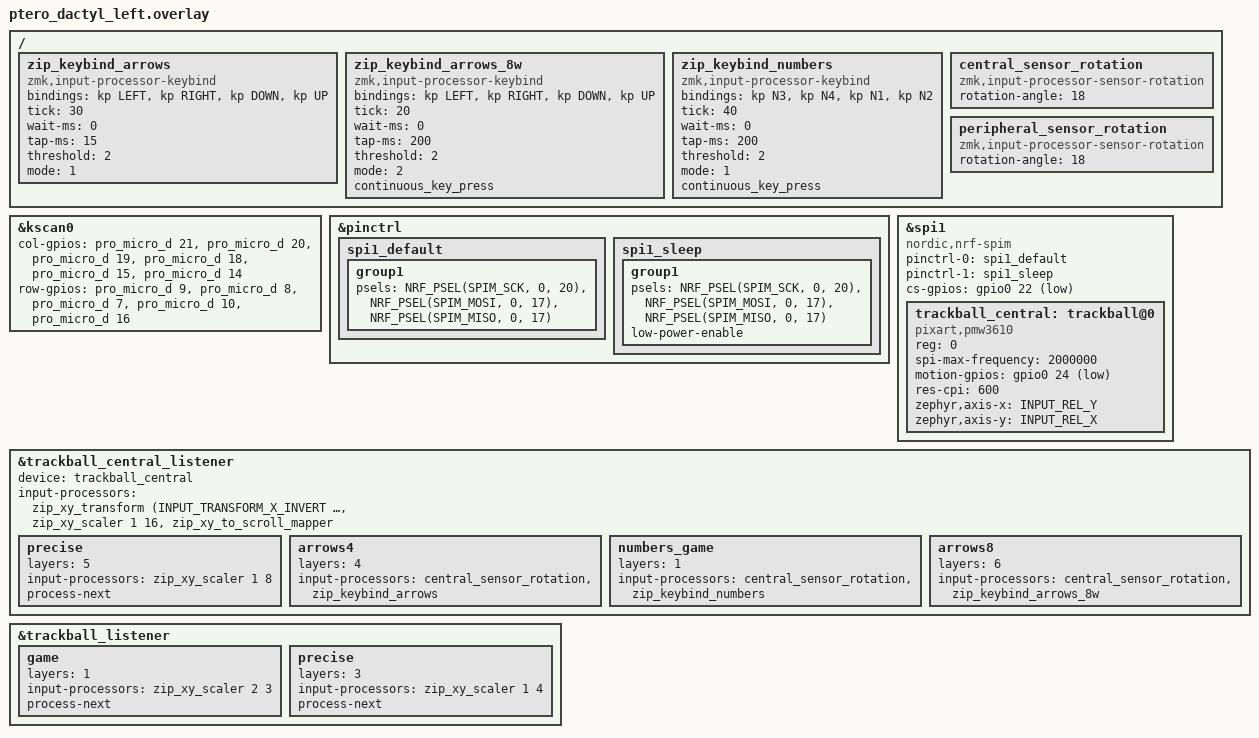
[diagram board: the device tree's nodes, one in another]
// This file was generated from a template. Edit it to match your keyboard.
// See https://zmk.dev/docs/development/hardware-integration/new-shield for more
// instructions.

#include "ptero_dactyl.dtsi"
#include <dt-bindings/zmk/input_transform.h>
#include <zephyr/dt-bindings/input/input-event-codes.h>
#include <input/processors.dtsi>

&kscan0 {
    // Replace these comments with the GPIO pins in the matrix for the left side.
    // See https://zmk.dev/docs/development/hardware-integration/new-shield#shield-overlays
    col-gpios
        = <&pro_micro_d 21 GPIO_ACTIVE_HIGH>
        , <&pro_micro_d 20 GPIO_ACTIVE_HIGH>
        , <&pro_micro_d 19 GPIO_ACTIVE_HIGH>
        , <&pro_micro_d 18 GPIO_ACTIVE_HIGH>
        , <&pro_micro_d 15 GPIO_ACTIVE_HIGH>
        , <&pro_micro_d 14 GPIO_ACTIVE_HIGH>
        ;

    row-gpios
        = <&pro_micro_d 9  (GPIO_ACTIVE_HIGH | GPIO_PULL_DOWN)>
        , <&pro_micro_d 8  (GPIO_ACTIVE_HIGH | GPIO_PULL_DOWN)>
        , <&pro_micro_d 7  (GPIO_ACTIVE_HIGH | GPIO_PULL_DOWN)>
        , <&pro_micro_d 10 (GPIO_ACTIVE_HIGH | GPIO_PULL_DOWN)>
        , <&pro_micro_d 16 (GPIO_ACTIVE_HIGH | GPIO_PULL_DOWN)>
        ;
};

&pinctrl {
    spi1_default: spi1_default {
        group1 {
            psels = <NRF_PSEL(SPIM_SCK, 0, 20)>,
                <NRF_PSEL(SPIM_MOSI, 0, 17)>,
                <NRF_PSEL(SPIM_MISO, 0, 17)>;
        };
    };

    spi1_sleep: spi1_sleep {
        group1 {
            psels = <NRF_PSEL(SPIM_SCK, 0, 20)>,
                <NRF_PSEL(SPIM_MOSI, 0, 17)>,
                <NRF_PSEL(SPIM_MISO, 0, 17)>;
            low-power-enable;
        };
    };
};

&spi1 {
    status = "okay";
    compatible = "nordic,nrf-spim";
    pinctrl-0 = <&spi1_default>;
    pinctrl-1 = <&spi1_sleep>;
    pinctrl-names = "default", "sleep";
    cs-gpios = <&gpio0 22 GPIO_ACTIVE_LOW>;

    trackball_central: trackball@0 {
        status = "okay";
        compatible = "pixart,pmw3610";
        reg = <0>;
        spi-max-frequency = <2000000>;
        motion-gpios = <&gpio0 24 (GPIO_ACTIVE_LOW | GPIO_PULL_UP)>;
        res-cpi = <600>;
        // evt-type = <INPUT_EV_REL>;
        zephyr,axis-x = <INPUT_REL_Y>;
        zephyr,axis-y = <INPUT_REL_X>;

        // force-awake;
        /* keep the sensor awake while ZMK activity state is ACTIVE,
           fallback to normal downshift mode after ZMK goes into IDLE / SLEEP mode.
           thus, the sensor would be a `wakeup-source` */
    };
};

#include <input/processors/zmk-input-processor-keybind.dtsi>
#include <input/processors/sensor_rotation.dtsi>

/ {
    zip_keybind_arrows: zip_keybind_arrows {
        compatible = "zmk,input-processor-keybind";
        #input-processor-cells = <0>;
        bindings = <&kp LEFT>,
                  <&kp RIGHT>,
                  <&kp DOWN>,
                  <&kp UP>;
        tick = <30>;
        wait-ms = <0>;
        tap-ms = <15>;
        threshold = <2>;
        mode = <1>;
    };

    zip_keybind_arrows_8w: zip_keybind_arrows_8w {
        compatible = "zmk,input-processor-keybind";
        #input-processor-cells = <0>;
        bindings = <&kp LEFT>,
                  <&kp RIGHT>,
                  <&kp DOWN>,
                  <&kp UP>;
        tick = <20>;
        wait-ms = <0>;
        tap-ms = <200>;
        threshold = <2>;
        mode = <2>;
        continuous_key_press;
    };

    zip_keybind_numbers: zip_keybind_numbers {
        compatible = "zmk,input-processor-keybind";
        #input-processor-cells = <0>;
        bindings = <&kp N3>,
                  <&kp N4>,
                  <&kp N1>,
                  <&kp N2>;
        tick = <40>;
        wait-ms = <0>;
        tap-ms = <200>;
        threshold = <2>;
        mode = <1>;
        continuous_key_press;
    };

    central_sensor_rotation: central_sensor_rotation {
        compatible = "zmk,input-processor-sensor-rotation";
        #input-processor-cells = <0>;
        rotation-angle = <18>;
    };

    peripheral_sensor_rotation: peripheral_sensor_rotation {
        compatible = "zmk,input-processor-sensor-rotation";
        #input-processor-cells = <0>;
        rotation-angle = <18>;
    };

};

&trackball_central_listener {
    status = "okay";
    device = <&trackball_central>;

    input-processors = <&zip_xy_transform (INPUT_TRANSFORM_X_INVERT | INPUT_TRANSFORM_Y_INVERT)>, <&zip_xy_scaler 1 16>, <&zip_xy_to_scroll_mapper>;

    precise {
        layers = <5>;
        input-processors = <&zip_xy_scaler 1 8>;
        process-next;
    };

    arrows4 {
        layers = <4>;
        input-processors = <&central_sensor_rotation>, <&zip_keybind_arrows>;
    };

    numbers_game {
        layers = <1>;
        input-processors = <&central_sensor_rotation>, <&zip_keybind_numbers>;
    };

    arrows8 {
        layers = <6>;
        input-processors = <&central_sensor_rotation>, <&zip_keybind_arrows_8w>;
    };
};

&trackball_listener {
    status = "okay";

    // input-processors = <&peripheral_sensor_rotation>; // , <&zip_temp_layer 2 400>

    game {
        layers = <1>;
        input-processors = <&zip_xy_scaler 2 3>;
        process-next;
    };

    precise {
        layers = <3>;
        input-processors = <&zip_xy_scaler 1 4>;
        process-next;
    };
};

